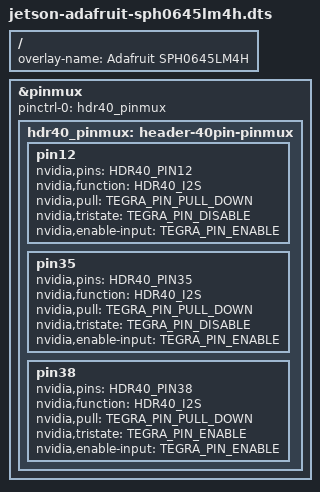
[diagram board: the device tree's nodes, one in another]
// SPDX-License-Identifier: GPL-2.0-only
/*
 * Jetson Device-tree overlay for Adafruit I2S MEMS Microphone Breakout
 * (SPH0645LM4H).
 *
 * Copyright (c) 2019 NVIDIA CORPORATION. All rights reserved.
 *
 */

#include <dt-bindings/pinctrl/pinctrl-tegra.h>

/ {
	overlay-name = "Adafruit SPH0645LM4H";
	compatible = JETSON_COMPATIBLE;

	fragment@0 {
		target = <&pinmux>;
		__overlay__ {
			pinctrl-names = "default";
			pinctrl-0 = <&hdr40_pinmux>;

			hdr40_pinmux: header-40pin-pinmux {
				pin12 {
					nvidia,pins = HDR40_PIN12;
					nvidia,function = HDR40_I2S;
					nvidia,pull = <TEGRA_PIN_PULL_DOWN>;
					nvidia,tristate = <TEGRA_PIN_DISABLE>;
					nvidia,enable-input = <TEGRA_PIN_ENABLE>;
				};

				pin35 {
					nvidia,pins = HDR40_PIN35;
					nvidia,function = HDR40_I2S;
					nvidia,pull = <TEGRA_PIN_PULL_DOWN>;
					nvidia,tristate = <TEGRA_PIN_DISABLE>;
					nvidia,enable-input = <TEGRA_PIN_ENABLE>;
				};

				pin38 {
					nvidia,pins = HDR40_PIN38;
					nvidia,function = HDR40_I2S;
					nvidia,pull = <TEGRA_PIN_PULL_DOWN>;
					nvidia,tristate = <TEGRA_PIN_ENABLE>;
					nvidia,enable-input = <TEGRA_PIN_ENABLE>;
				};
			};
		};
	};
};
